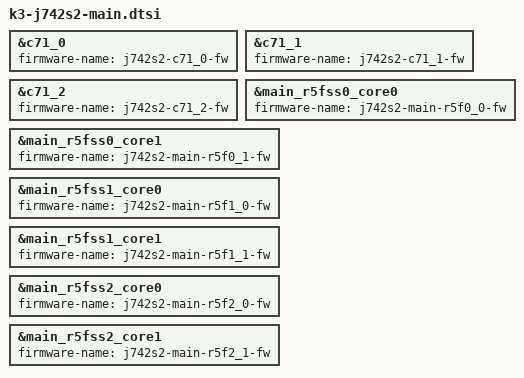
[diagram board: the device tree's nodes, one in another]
// SPDX-License-Identifier: GPL-2.0-only OR MIT
/*
 * Device Tree Source for J742S2 SoC Family
 *
 * TRM: https://www.ti.com/lit/pdf/spruje3
 *
 * Copyright (C) 2024 Texas Instruments Incorporated - https://www.ti.com/
 *
 */

&c71_0 {
	firmware-name = "j742s2-c71_0-fw";
};

&c71_1 {
	firmware-name = "j742s2-c71_1-fw";
};

&c71_2 {
	firmware-name = "j742s2-c71_2-fw";
};

&main_r5fss0_core0 {
	firmware-name = "j742s2-main-r5f0_0-fw";
};

&main_r5fss0_core1 {
	firmware-name = "j742s2-main-r5f0_1-fw";
};

&main_r5fss1_core0 {
	firmware-name = "j742s2-main-r5f1_0-fw";
};

&main_r5fss1_core1 {
	firmware-name = "j742s2-main-r5f1_1-fw";
};

&main_r5fss2_core0 {
	firmware-name = "j742s2-main-r5f2_0-fw";
};

&main_r5fss2_core1 {
	firmware-name = "j742s2-main-r5f2_1-fw";
};
